# STM32H533 register map
File version: 1.3
CPU: CM33 r0p0, little endian, MPU, FPU, 4 interrupt priority bits
Registers are 32-bit, read-write, reset 0x0 unless marked. A register's access mark holds for its fields unless they carry their own. Offsets are from the block's base; [hi:lo] are bit positions; {n}, {i} and the like mark numbered series; 'fields as' and 'values as' point back to an identical list.

## TIM12 — General-purpose timers
Base 0x40001800
Same registers: SEC_TIM12 0x50001800
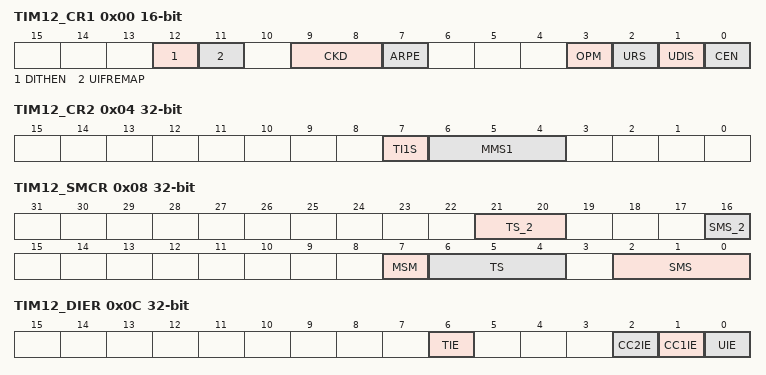
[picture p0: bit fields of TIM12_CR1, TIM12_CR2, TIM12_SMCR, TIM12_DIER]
0x00 TIM12_CR1 16-bit — TIM12 control register 1
  [12] DITHEN — Dithering Enable
    0=Dithering disabled; 1=Dithering enabled
  [11] UIFREMAP — UIF status bit remapping
    0=No remapping. UIF status bit is not copied to TIMx_CNT register bit 31.; 1=Remapping enabled. UIF status bit is copied to TIMx_CNT register bit 31.
  [9:8] CKD — Clock division
    0=tDTS = ttim_ker_ck; 1=tDTS = 2 ttim_ker_ck; 2=tDTS = 4 ttim_ker_ck
  [7] ARPE — Auto-reload preload enable
    0=TIMx_ARR register is not buffered; 1=TIMx_ARR register is buffered
  [3] OPM — One-pulse mode
    0=Counter is not stopped at update event; 1=Counter stops counting at the next update event (clearing the bit CEN)
  [2] URS — Update request source
    0=Any of the following events generate an update interrupt or DMA request if enabled. These events can be:; 1=Only counter overflow/underflow generates an update interrupt or DMA request if enabled
  [1] UDIS — Update disable
    0=UEV enabled. The Update (UEV) event is generated by one of the following events:; 1=UEV disabled. The Update event is not generated, shadow registers keep their value (ARR, PSC, CCRx). However the counter and the prescaler are reinitialized if the UG bit is set or if a hardware reset is received from the slave mode controller.
  [0] CEN — Counter enable
    0=Counter disabled; 1=Counter enabled
0x04 TIM12_CR2 — TIM12 control register 2
  [7] TI1S — tim_ti1 selection
    0=The tim_ti1_in[15..0] multiplexer output is to tim_ti1 input; 1=The tim_ti1_in[15..0], tim_ti2_in[15..0] and tim_ti3_in[15..0] multiplexers outputs are XORed and connected to the tim_ti1 input. See also sensors on page 1494.
  [6:4] MMS1 — Master mode selection
    0=Reset - the UG bit from the TIMx_EGR register is used as trigger output (tim_trgo). If the reset is generated by the trigger input (slave mode controller configured in reset mode) then the signal on tim_trgo is delayed compared to the actual reset.; 1=Enable - the Counter enable signal, CNT_EN, is used as trigger output (tim_trgo). It is useful to start several timers at the same time or to control a window in which a slave timer is enabled. The Counter Enable signal is generated by a logic AND between CEN control bit and the trigger input when configured in gated mode.When the Counter Enable signal is controlled by the trigger input, there is a delay on; 2=Update - The update event is selected as trigger output (tim_trgo). For instance a master timer can then be used as a prescaler for a slave timer.; 3=Compare Pulse - The trigger output send a positive pulse when the CC1IF flag is to be set (even if it was already high), as soon as a capture or a compare match occurred (tim_trgo); {v}=Compare - tim_oc{v-3}refc signal is used as trigger output (tim_trgo) (v=4..7)
0x08 TIM12_SMCR — TIM12 slave mode control register
  [21:20] TS_2 — Trigger selection (see bits 21:20 for TS[4:3])
    {v}=Internal trigger {v} (tim_itr{v}) (v=0..3)
  [16] SMS_2 — Slave mode selection
    0=Slave mode disabled - if CEN = 1 then the prescaler is clocked directly by the internal clock; 1=Encoder mode 1 - Counter counts up/down on tim_ti1fp1 edge depending on tim_ti2fp2 level
  [7] MSM — Master/Slave mode
    0=No action; 1=The effect of an event on the trigger input (tim_trgi) is delayed to allow a perfect synchronization between the current timer and its slaves (through tim_trgo). It is useful if we want to synchronize several timers on a single external event.
  [6:4] TS — Trigger selection (see bits 21:20 for TS[4:3])
    {v}=Internal trigger {v} (tim_itr{v}) (v=0..3); 4=tim_ti1 edge detector (tim_ti1f_ed); 5=Filtered timer input 1 (tim_ti1fp1); 6=Filtered timer input 2 (tim_ti2fp2); 7=External trigger input (tim_etrf)
  [2:0] SMS — Slave mode selection
    0=Slave mode disabled - if CEN = 1 then the prescaler is clocked directly by the internal clock; 1=Encoder mode 1 - Counter counts up/down on tim_ti1fp1 edge depending on tim_ti2fp2 level; 2=Encoder mode 2 - Counter counts up/down on tim_ti2fp2 edge depending on tim_ti1fp1 level; 3=Encoder mode 3 - Counter counts up/down on both tim_ti1fp1 and tim_ti2fp2 edges depending on the level of the other input; 4=Reset Mode - Rising edge of the selected trigger input (tim_trgi) reinitializes the counter and generates an update of the registers; 5=Gated Mode - The counter clock is enabled when the trigger input (tim_trgi) is high. The counter stops (but is not reset) as soon as the trigger becomes low. Both start and stop of the counter are controlled.; 6=Trigger Mode - The counter starts at a rising edge of the trigger tim_trgi (but it is not reset). Only the start of the counter is controlled.; 7=External Clock Mode 1 - Rising edges of the selected trigger (tim_trgi) clock the counter
0x0C TIM12_DIER — TIM12 DMA/Interrupt enable register
  [6] TIE — Trigger interrupt enable
    0=Trigger interrupt disabled; 1=Trigger interrupt enabled
  [2] CC2IE — Capture/Compare 2 interrupt enable
    0=CC2 interrupt disabled; 1=CC2 interrupt enabled
  [1] CC1IE — Capture/Compare 1 interrupt enable
    0=CC1 interrupt disabled; 1=CC1 interrupt enabled
  [0] UIE — Update interrupt enable
    0=Update interrupt disabled; 1=Update interrupt enabled
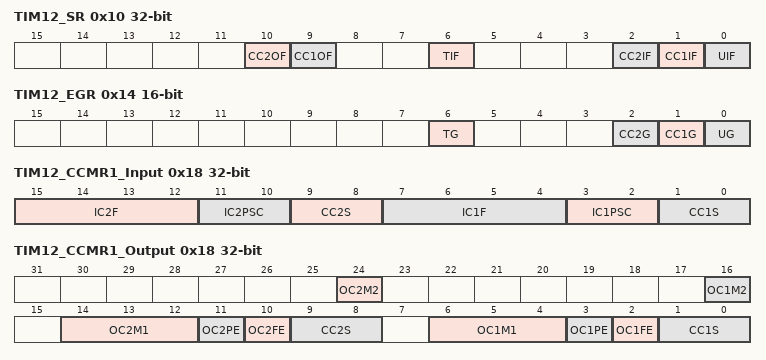
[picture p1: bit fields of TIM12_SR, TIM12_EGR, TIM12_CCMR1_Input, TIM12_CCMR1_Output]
0x10 TIM12_SR — TIM12 status register
  [10] CC2OF — Capture/compare 2 overcapture flag
  [9] CC1OF — Capture/Compare 1 overcapture flag
    0=No overcapture has been detected; 1=The counter value has been captured in TIMx_CCR1 register while CC1IF flag was already set
  [6] TIF — Trigger interrupt flag
    0=No trigger event occurred; 1=Trigger interrupt pending
  [2] CC2IF — Capture/Compare 2 interrupt flag
  [1] CC1IF — Capture/compare 1 interrupt flag
    0=No compare match / No input capture occurred; 1=A compare match or an input capture occurred
  [0] UIF — Update interrupt flag
    0=No update occurred; 1=Update interrupt pending. This bit is set by hardware when the registers are updated:
0x14 TIM12_EGR 16-bit wo — TIM12 event generation register
  [6] TG — Trigger generation
    0=No action; 1=The TIF flag is set in TIMx_SR register. Related interrupt or DMA transfer can occur if enabled.
  [2] CC2G — Capture/compare 2 generation
  [1] CC1G — Capture/compare 1 generation
    0=No action; 1=A capture/compare event is generated on channel 1:
  [0] UG — Update generation
    0=No action; 1=Re-initialize the counter and generates an update of the registers. Note that the prescaler counter is cleared too (anyway the prescaler ratio is not affected). The counter is cleared if the center-aligned mode is selected or if DIR=0 (upcounting), else it takes the auto-reload value (TIMx_ARR) if DIR=1 (downcounting).
0x18 TIM12_CCMR1_Input — TIM12 capture/compare mode register 1 [alternate]
  [15:12] IC2F — Input capture 2 filter
  [11:10] IC2PSC — Input capture 2 prescaler
  [9:8] CC2S — Capture/compare 2 selection
    0=CC2 channel is configured as output; 1=CC2 channel is configured as input, tim_ic2 is mapped on tim_ti2; 2=CC2 channel is configured as input, tim_ic2 is mapped on tim_ti1; 3=CC2 channel is configured as input, tim_ic2 is mapped on tim_trc. This mode is working only if an internal trigger input is selected through TS bit (TIMx_SMCR register)
  [7:4] IC1F — Input capture 1 filter
    0=No filter, sampling is done at fDTS; 1=fSAMPLING=ftim_ker_ck, N=2; 2=fSAMPLING=ftim_ker_ck, N=4; 3=fSAMPLING=ftim_ker_ck, N=8; 4=fSAMPLING=fDTS/2, N=6; 5=fSAMPLING=fDTS/2, N=8; 6=fSAMPLING=fDTS/4, N=6; 7=fSAMPLING=fDTS/4, N=8; 8=fSAMPLING=fDTS/8, N=6; 9=fSAMPLING=fDTS/8, N=8; 10=fSAMPLING=fDTS/16, N=5; 11=fSAMPLING=fDTS/16, N=6; 12=fSAMPLING=fDTS/16, N=8; 13=fSAMPLING=fDTS/32, N=5; 14=fSAMPLING=fDTS/32, N=6; 15=fSAMPLING=fDTS/32, N=8
  [3:2] IC1PSC — Input capture 1 prescaler
    0=no prescaler, capture is done each time an edge is detected on the capture input; 1=capture is done once every 2 events; 2=capture is done once every 4 events; 3=capture is done once every 8 events
  [1:0] CC1S — Capture/Compare 1 selection
    0=CC1 channel is configured as output; 1=CC1 channel is configured as input, tim_ic1 is mapped on tim_ti1; 2=CC1 channel is configured as input, tim_ic1 is mapped on tim_ti2; 3=CC1 channel is configured as input, tim_ic1 is mapped on tim_trc. This mode is working only if an internal trigger input is selected through TS bit (TIMx_SMCR register)
0x18 TIM12_CCMR1_Output (alternate view of TIM12_CCMR1_Input) — TIM12 capture/compare mode register 1 [alternate]
  [24] OC2M2 — Output compare 2 mode
  [16] OC1M2 — Output compare 1 mode
    0=Frozen - The comparison between the output compare register TIMx_CCR1 and the counter TIMx_CNT has no effect on the outputs.(this mode is used to generate a timing base); 1=Set channel 1 to active level on match. tim_oc1ref signal is forced high when the counter TIMx_CNT matches the capture/compare register 1 (TIMx_CCR1).
  [14:12] OC2M1 — Output compare 2 mode
  [11] OC2PE — Output compare 2 preload enable
  [10] OC2FE — Output compare 2 fast enable
  [9:8] CC2S — Capture/Compare 2 selection
    0=CC2 channel is configured as output; 1=CC2 channel is configured as input, tim_ic2 is mapped on tim_ti2; 2=CC2 channel is configured as input, tim_ic2 is mapped on tim_ti1; 3=CC2 channel is configured as input, tim_ic2 is mapped on tim_trc. This mode is working only if an internal trigger input is selected through the TS bit (TIMx_SMCR register)
  [6:4] OC1M1 — Output compare 1 mode
    0=Frozen - The comparison between the output compare register TIMx_CCR1 and the counter TIMx_CNT has no effect on the outputs.(this mode is used to generate a timing base); 1=Set channel 1 to active level on match. tim_oc1ref signal is forced high when the counter TIMx_CNT matches the capture/compare register 1 (TIMx_CCR1).; 2=Set channel 1 to inactive level on match. tim_oc1ref signal is forced low when the counter TIMx_CNT matches the capture/compare register 1 (TIMx_CCR1).; 3=Toggle - tim_oc1ref toggles when TIMx_CNT=TIMx_CCR1; 4=Force inactive level - tim_oc1ref is forced low; 5=Force active level - tim_oc1ref is forced high; 6=PWM mode 1 - In upcounting, channel 1 is active as long as TIMx_CNTless thanTIMx_CCR1 else inactive. In downcounting, channel 1 is inactive (tim_oc1ref=0) as long as TIMx_CNT>TIMx_CCR1 else active (tim_oc1ref=1).; 7=PWM mode 2 - In upcounting, channel 1 is inactive as long as TIMx_CNTless thanTIMx_CCR1 else active. In downcounting, channel 1 is active as long as TIMx_CNT>TIMx_CCR1 else inactive.
  [3] OC1PE — Output compare 1 preload enable
    0=Preload register on TIMx_CCR1 disabled. TIMx_CCR1 can be written at anytime, the new value is taken in account immediately.; 1=Preload register on TIMx_CCR1 enabled. Read/Write operations access the preload register. TIMx_CCR1 preload value is loaded in the active register at each update event.
  [2] OC1FE — Output compare 1 fast enable
    0=CC1 behaves normally depending on counter and CCR1 values even when the trigger is ON. The minimum delay to activate CC1 output when an edge occurs on the trigger input is 5 clock cycles.; 1=An active edge on the trigger input acts like a compare match on CC1 output. Then, OC is set to the compare level independently from the result of the comparison. Delay to sample the trigger input and to activate CC1 output is reduced to 3 clock cycles. OCFE acts only if the channel is configured in PWM1 or PWM2 mode.
  [1:0] CC1S — Capture/Compare 1 selection
    values as TIM12_CCMR1_Input.CC1S
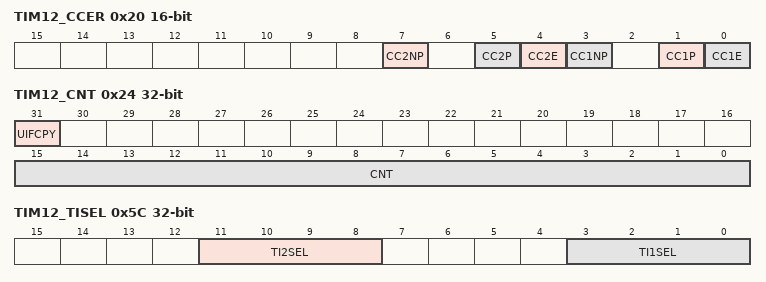
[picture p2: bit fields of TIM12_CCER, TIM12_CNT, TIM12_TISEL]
0x20 TIM12_CCER 16-bit — TIM12 capture/compare enable register
  [7] CC2NP — Capture/Compare 2 output Polarity.
  [5] CC2P — Capture/Compare 2 output Polarity.
  [4] CC2E — Capture/Compare 2 output enable.
  [3] CC1NP — Capture/Compare 1 output Polarity.
  [1] CC1P — Capture/Compare 1 output Polarity.
    0=OC1 active high (output mode) / Edge sensitivity selection (input mode, see below); 1=OC1 active low (output mode) / Edge sensitivity selection (input mode, see below)
  [0] CC1E — Capture/Compare 1 output enable.
    0=Capture mode disabled / OC1 is not active; 1=Capture mode enabled / OC1 signal is output on the corresponding output pin
0x24 TIM12_CNT — TIM12 counter
  [31] UIFCPY — UIF Copy
  [15:0] CNT — or UIFCPY: Value depends on IUFREMAP in TIMx_CR1.
0x28 TIM12_PSC 16-bit — TIM12 prescaler
  [15:0] PSC — Prescaler value
0x2C TIM12_ARR reset 0xFFFFFFFF — TIM12 auto-reload register
  [19:0] ARR — Auto-reload value
0x34 TIM12_CCR1 — TIM12 capture/compare register 1
  [19:0] CCR1 — Capture/compare 1 value
0x38 TIM12_CCR2 — TIM12 capture/compare register 2
  [19:0] CCR2 — Capture/compare 2 value
0x5C TIM12_TISEL — TIM12 timer input selection register
  [11:8] TI2SEL — Selects tim_ti2[0..15] input
    0=tim_ti2_in0: TIMx_CH2; 1=tim_ti2_in1; 15=tim_ti2_in15
  [3:0] TI1SEL — Selects tim_ti1[0..15] input
    0=tim_ti1_in0: TIMx_CH1; 1=tim_ti1_in1; 15=tim_ti1_in15
